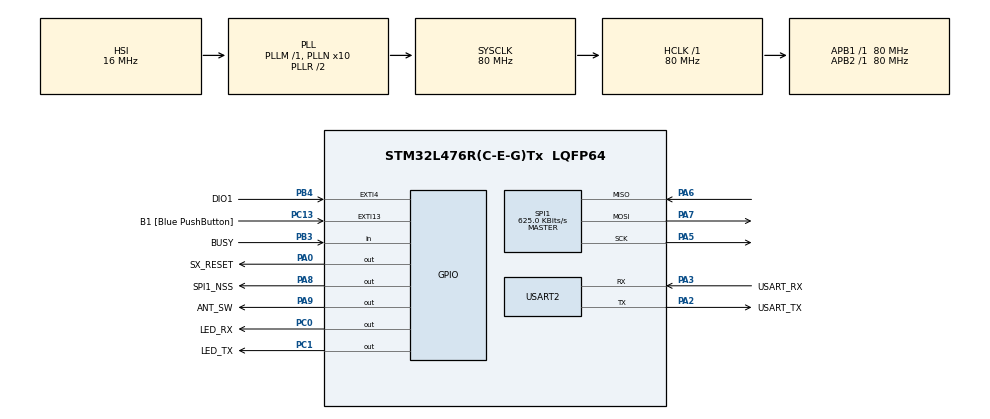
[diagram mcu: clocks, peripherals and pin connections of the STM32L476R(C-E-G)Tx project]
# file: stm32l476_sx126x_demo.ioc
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Mcu.Family=STM32L4
Mcu.Name=STM32L476R(C-E-G)Tx
Mcu.Package=LQFP64
NVIC.EXTI15_10_IRQn=true\:0\:0\:false\:false\:true\:true\:true
NVIC.EXTI4_IRQn=true\:0\:0\:false\:false\:true\:true\:true
NVIC.PriorityGroup=NVIC_PRIORITYGROUP_4
NVIC.RTC_Alarm_IRQn=true\:1\:0\:true\:false\:true\:true\:true
PA0.GPIO_Label=SX_RESET
PA0.Signal=GPIO_Output
PA13\ (JTMS-SWDIO).GPIO_Label=TMS
PA13\ (JTMS-SWDIO).Mode=Serial_Wire
PA13\ (JTMS-SWDIO).Signal=SYS_JTMS-SWDIO
PA14\ (JTCK-SWCLK).GPIO_Label=TCK
PA14\ (JTCK-SWCLK).Mode=Serial_Wire
PA14\ (JTCK-SWCLK).Signal=SYS_JTCK-SWCLK
PA2.GPIO_Label=USART_TX
PA2.GPIO_Mode=GPIO_MODE_AF_PP
PA2.GPIO_PuPd=GPIO_NOPULL
PA2.GPIO_Speed=GPIO_SPEED_FREQ_VERY_HIGH
PA2.Mode=Asynchronous
PA2.Signal=USART2_TX
PA3.GPIO_Label=USART_RX
PA3.GPIO_Mode=GPIO_MODE_AF_PP
PA3.GPIO_PuPd=GPIO_PULLUP
PA3.GPIO_Speed=GPIO_SPEED_FREQ_VERY_HIGH
PA3.Mode=Asynchronous
PA3.Signal=USART2_RX
PA5.Mode=Full_Duplex_Master
PA5.Signal=SPI1_SCK
PA6.Mode=Full_Duplex_Master
PA6.Signal=SPI1_MISO
PA7.Mode=Full_Duplex_Master
PA7.Signal=SPI1_MOSI
PA8.GPIO_Label=SPI1_NSS
PA8.PinState=GPIO_PIN_SET
PA8.Signal=GPIO_Output
PA9.GPIO_Label=ANT_SW
PA9.Signal=GPIO_Output
PB3\ (JTDO-TRACESWO).GPIO_Label=BUSY
PB3\ (JTDO-TRACESWO).GPIO_PuPd=GPIO_PULLUP
PB3\ (JTDO-TRACESWO).Signal=GPIO_Input
PB4\ (NJTRST).GPIO_Label=DIO1
PB4\ (NJTRST).GPIO_PuPd=GPIO_PULLUP
PB4\ (NJTRST).Signal=GPXTI4
PC0.GPIO_Label=LED_RX
PC0.Signal=GPIO_Output
PC1.GPIO_Label=LED_TX
PC1.Signal=GPIO_Output
PC13.GPIO_Label=B1 [Blue PushButton]
PC13.GPIO_ModeDefaultEXTI=GPIO_MODE_IT_FALLING
PC13.GPIO_PuPd=GPIO_NOPULL
PC13.Signal=GPXTI13
PC14-OSC32_IN\ (PC14).Mode=LSE-External-Oscillator
PC14-OSC32_IN\ (PC14).Signal=RCC_OSC32_IN
PC15-OSC32_OUT\ (PC15).Mode=LSE-External-Oscillator
PC15-OSC32_OUT\ (PC15).Signal=RCC_OSC32_OUT
ProjectManager.HeapSize=0x200
ProjectManager.StackSize=0x400
ProjectManager.TargetToolchain=Makefile
RCC.ADCFreq_Value=64000000
RCC.AHBFreq_Value=80000000
RCC.APB1Freq_Value=80000000
RCC.APB1TimFreq_Value=80000000
RCC.APB2Freq_Value=80000000
RCC.APB2TimFreq_Value=80000000
RCC.CortexFreq_Value=80000000
RCC.HCLKFreq_Value=80000000
RCC.HSE_VALUE=8000000
RCC.HSI_VALUE=16000000
RCC.MSI_VALUE=4000000
RCC.PLLN=10
RCC.PLLSourceVirtual=RCC_PLLSOURCE_HSI
RCC.PREFETCH_ENABLE=1
RCC.SYSCLKFreq_VALUE=80000000
RCC.SYSCLKSource=RCC_SYSCLKSOURCE_PLLCLK
RCC.USBFreq_Value=64000000
RCC.VCOOutputFreq_Value=160000000
RTC.Alarm-Alarm\ A=RTC_ALARM_A
RTC.AsynchPrediv=31
RTC.Format=RTC_FORMAT_BIN
RTC.SynchPrediv=1023
SPI1.BaudRatePrescaler=SPI_BAUDRATEPRESCALER_128
SPI1.CLKPhase=SPI_PHASE_2EDGE
SPI1.CalculateBaudRate=625.0 KBits/s
SPI1.DataSize=SPI_DATASIZE_8BIT
SPI1.Direction=SPI_DIRECTION_2LINES
SPI1.Mode=SPI_MODE_MASTER
SPI1.VirtualType=VM_MASTER
USART2.VirtualMode-Asynchronous=VM_ASYNC
VP_RTC_VS_RTC_Activate.Mode=RTC_Enabled
VP_RTC_VS_RTC_Alarm_A_Intern.Mode=Alarm A
VP_RTC_VS_RTC_Calendar.Mode=RTC_Calendar
board=NUCLEO-L476RG

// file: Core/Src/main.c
/* USER CODE BEGIN Header */
/**
  ******************************************************************************
  * @file           : main.c
  * @brief          : Main program body
  ******************************************************************************
  * @attention
  *
  * <h2><center>&copy; Copyright (c) 2021 STMicroelectronics.
  * All rights reserved.</center></h2>
  *
  * This software component is licensed by ST under BSD 3-Clause license,
  * the "License"; You may not use this file except in compliance with the
  * License. You may obtain a copy of the License at:
  *                        opensource.org/licenses/BSD-3-Clause
  *
  ******************************************************************************
  */
/* USER CODE END Header */
#include "main.h"

/* USER CODE BEGIN Includes */
#include "app_sx126x.h"
/* USER CODE END Includes */

RTC_HandleTypeDef hrtc;

SPI_HandleTypeDef hspi1;

UART_HandleTypeDef huart2;

void SystemClock_Config(void);
static void MX_GPIO_Init(void);
static void MX_SPI1_Init(void);
static void MX_USART2_UART_Init(void);
static void MX_RTC_Init(void);

/* USER CODE BEGIN 0 */
int _write(int fd, char *pBuffer, int size)
{
  for (int i = 0; i < size; i++)
  {
    HAL_UART_Transmit(&huart2, (uint8_t *)(pBuffer+i), 1, 1000);
  }
  return size;
}
/* USER CODE END 0 */

int main(void)
{

  /* MCU Configuration--------------------------------------------------------*/

  /* Reset of all peripherals, Initializes the Flash interface and the Systick. */
  HAL_Init();

  /* Configure the system clock */
  SystemClock_Config();

  /* Initialize all configured peripherals */
  MX_GPIO_Init();
  MX_SPI1_Init();
  MX_USART2_UART_Init();
  MX_RTC_Init();
  /* USER CODE BEGIN 2 */
  sx126x_init();
  /* USER CODE END 2 */

  /* Infinite loop */
  /* USER CODE BEGIN WHILE */
  while (1)
  {
    // printf("this is sx126x application\n");
    // sx126x_rx_packet();
    register_test();
    // sx126x_tx_packet(0,0);
    HAL_Delay(100);
    // sx126x_rx_packet();
    // packet_rx();

    // printf("tx packet\n");
    /* USER CODE END WHILE */

  }
}

void SystemClock_Config(void)
{
  RCC_OscInitTypeDef RCC_OscInitStruct = {0};
  RCC_ClkInitTypeDef RCC_ClkInitStruct = {0};
  RCC_PeriphCLKInitTypeDef PeriphClkInit = {0};

  /** Initializes the RCC Oscillators according to the specified parameters
  * in the RCC_OscInitTypeDef structure.
  */
  RCC_OscInitStruct.OscillatorType = RCC_OSCILLATORTYPE_HSI|RCC_OSCILLATORTYPE_LSI;
  RCC_OscInitStruct.HSIState = RCC_HSI_ON;
  RCC_OscInitStruct.HSICalibrationValue = RCC_HSICALIBRATION_DEFAULT;
  RCC_OscInitStruct.LSIState = RCC_LSI_ON;
  RCC_OscInitStruct.PLL.PLLState = RCC_PLL_ON;
  RCC_OscInitStruct.PLL.PLLSource = RCC_PLLSOURCE_HSI;
  RCC_OscInitStruct.PLL.PLLM = 1;
  RCC_OscInitStruct.PLL.PLLN = 10;
  RCC_OscInitStruct.PLL.PLLP = RCC_PLLP_DIV7;
  RCC_OscInitStruct.PLL.PLLQ = RCC_PLLQ_DIV2;
  RCC_OscInitStruct.PLL.PLLR = RCC_PLLR_DIV2;
  if (HAL_RCC_OscConfig(&RCC_OscInitStruct) != HAL_OK)
  {
    Error_Handler();
  }
  /** Initializes the CPU, AHB and APB buses clocks
  */
  RCC_ClkInitStruct.ClockType = RCC_CLOCKTYPE_HCLK|RCC_CLOCKTYPE_SYSCLK
                              |RCC_CLOCKTYPE_PCLK1|RCC_CLOCKTYPE_PCLK2;
  RCC_ClkInitStruct.SYSCLKSource = RCC_SYSCLKSOURCE_PLLCLK;
  RCC_ClkInitStruct.AHBCLKDivider = RCC_SYSCLK_DIV1;
  RCC_ClkInitStruct.APB1CLKDivider = RCC_HCLK_DIV1;
  RCC_ClkInitStruct.APB2CLKDivider = RCC_HCLK_DIV1;

  if (HAL_RCC_ClockConfig(&RCC_ClkInitStruct, FLASH_LATENCY_4) != HAL_OK)
  {
    Error_Handler();
  }
  PeriphClkInit.PeriphClockSelection = RCC_PERIPHCLK_RTC|RCC_PERIPHCLK_USART2;
  PeriphClkInit.Usart2ClockSelection = RCC_USART2CLKSOURCE_PCLK1;
  PeriphClkInit.RTCClockSelection = RCC_RTCCLKSOURCE_LSI;
  if (HAL_RCCEx_PeriphCLKConfig(&PeriphClkInit) != HAL_OK)
  {
    Error_Handler();
  }
  /** Configure the main internal regulator output voltage
  */
  if (HAL_PWREx_ControlVoltageScaling(PWR_REGULATOR_VOLTAGE_SCALE1) != HAL_OK)
  {
    Error_Handler();
  }
}

static void MX_RTC_Init(void)
{

  RTC_TimeTypeDef sTime = {0};
  RTC_DateTypeDef sDate = {0};
  RTC_AlarmTypeDef sAlarm = {0};

  /** Initialize RTC Only
  */
  hrtc.Instance = RTC;
  hrtc.Init.HourFormat = RTC_HOURFORMAT_24;
  hrtc.Init.AsynchPrediv = 31;
  hrtc.Init.SynchPrediv = 1023;
  hrtc.Init.OutPut = RTC_OUTPUT_DISABLE;
  hrtc.Init.OutPutRemap = RTC_OUTPUT_REMAP_NONE;
  hrtc.Init.OutPutPolarity = RTC_OUTPUT_POLARITY_HIGH;
  hrtc.Init.OutPutType = RTC_OUTPUT_TYPE_OPENDRAIN;
  if (HAL_RTC_Init(&hrtc) != HAL_OK)
  {
    Error_Handler();
  }

  /** Initialize RTC and set the Time and Date
  */
  sTime.Hours = 0;
  sTime.Minutes = 0;
  sTime.Seconds = 0;
  sTime.DayLightSaving = RTC_DAYLIGHTSAVING_NONE;
  sTime.StoreOperation = RTC_STOREOPERATION_RESET;
  if (HAL_RTC_SetTime(&hrtc, &sTime, RTC_FORMAT_BIN) != HAL_OK)
  {
    Error_Handler();
  }
  sDate.WeekDay = RTC_WEEKDAY_MONDAY;
  sDate.Month = RTC_MONTH_JANUARY;
  sDate.Date = 1;
  sDate.Year = 0;

  if (HAL_RTC_SetDate(&hrtc, &sDate, RTC_FORMAT_BIN) != HAL_OK)
  {
    Error_Handler();
  }
  /** Enable the Alarm A
  */
  sAlarm.AlarmTime.Hours = 0;
  sAlarm.AlarmTime.Minutes = 0;
  sAlarm.AlarmTime.Seconds = 0;
  sAlarm.AlarmTime.SubSeconds = 0;
  sAlarm.AlarmTime.DayLightSaving = RTC_DAYLIGHTSAVING_NONE;
  sAlarm.AlarmTime.StoreOperation = RTC_STOREOPERATION_RESET;
  sAlarm.AlarmMask = RTC_ALARMMASK_NONE;
  sAlarm.AlarmSubSecondMask = RTC_ALARMSUBSECONDMASK_ALL;
  sAlarm.AlarmDateWeekDaySel = RTC_ALARMDATEWEEKDAYSEL_DATE;
  sAlarm.AlarmDateWeekDay = 1;
  sAlarm.Alarm = RTC_ALARM_A;
  if (HAL_RTC_SetAlarm_IT(&hrtc, &sAlarm, RTC_FORMAT_BIN) != HAL_OK)
  {
    Error_Handler();
  }

}

static void MX_SPI1_Init(void)
{

  /* SPI1 parameter configuration*/
  hspi1.Instance = SPI1;
  hspi1.Init.Mode = SPI_MODE_MASTER;
  hspi1.Init.Direction = SPI_DIRECTION_2LINES;
  hspi1.Init.DataSize = SPI_DATASIZE_8BIT;
  hspi1.Init.CLKPolarity = SPI_POLARITY_LOW;
  hspi1.Init.CLKPhase = SPI_PHASE_2EDGE;
  hspi1.Init.NSS = SPI_NSS_SOFT;
  hspi1.Init.BaudRatePrescaler = SPI_BAUDRATEPRESCALER_128;
  hspi1.Init.FirstBit = SPI_FIRSTBIT_MSB;
  hspi1.Init.TIMode = SPI_TIMODE_DISABLE;
  hspi1.Init.CRCCalculation = SPI_CRCCALCULATION_DISABLE;
  hspi1.Init.CRCPolynomial = 7;
  hspi1.Init.CRCLength = SPI_CRC_LENGTH_DATASIZE;
  hspi1.Init.NSSPMode = SPI_NSS_PULSE_DISABLE;
  if (HAL_SPI_Init(&hspi1) != HAL_OK)
  {
    Error_Handler();
  }

}

static void MX_USART2_UART_Init(void)
{

  huart2.Instance = USART2;
  huart2.Init.BaudRate = 115200;
  huart2.Init.WordLength = UART_WORDLENGTH_8B;
  huart2.Init.StopBits = UART_STOPBITS_1;
  huart2.Init.Parity = UART_PARITY_NONE;
  huart2.Init.Mode = UART_MODE_TX_RX;
  huart2.Init.HwFlowCtl = UART_HWCONTROL_NONE;
  huart2.Init.OverSampling = UART_OVERSAMPLING_16;
  huart2.Init.OneBitSampling = UART_ONE_BIT_SAMPLE_DISABLE;
  huart2.AdvancedInit.AdvFeatureInit = UART_ADVFEATURE_NO_INIT;
  if (HAL_UART_Init(&huart2) != HAL_OK)
  {
    Error_Handler();
  }

}

static void MX_GPIO_Init(void)
{
  GPIO_InitTypeDef GPIO_InitStruct = {0};

  /* GPIO Ports Clock Enable */
  __HAL_RCC_GPIOC_CLK_ENABLE();
  __HAL_RCC_GPIOA_CLK_ENABLE();
  __HAL_RCC_GPIOB_CLK_ENABLE();

  /*Configure GPIO pin Output Level */
  HAL_GPIO_WritePin(GPIOC, LED_RX_Pin|LED_TX_Pin, GPIO_PIN_RESET);

  /*Configure GPIO pin Output Level */
  HAL_GPIO_WritePin(GPIOA, SX_RESET_Pin|ANT_SW_Pin, GPIO_PIN_RESET);

  /*Configure GPIO pin Output Level */
  HAL_GPIO_WritePin(SPI1_NSS_GPIO_Port, SPI1_NSS_Pin, GPIO_PIN_SET);

  /*Configure GPIO pin : B1_Pin */
  GPIO_InitStruct.Pin = B1_Pin;
  GPIO_InitStruct.Mode = GPIO_MODE_IT_FALLING;
  GPIO_InitStruct.Pull = GPIO_NOPULL;
  HAL_GPIO_Init(B1_GPIO_Port, &GPIO_InitStruct);

  /*Configure GPIO pins : LED_RX_Pin LED_TX_Pin */
  GPIO_InitStruct.Pin = LED_RX_Pin|LED_TX_Pin;
  GPIO_InitStruct.Mode = GPIO_MODE_OUTPUT_PP;
  GPIO_InitStruct.Pull = GPIO_NOPULL;
  GPIO_InitStruct.Speed = GPIO_SPEED_FREQ_LOW;
  HAL_GPIO_Init(GPIOC, &GPIO_InitStruct);

  /*Configure GPIO pins : SX_RESET_Pin SPI1_NSS_Pin ANT_SW_Pin */
  GPIO_InitStruct.Pin = SX_RESET_Pin|SPI1_NSS_Pin|ANT_SW_Pin;
  GPIO_InitStruct.Mode = GPIO_MODE_OUTPUT_PP;
  GPIO_InitStruct.Pull = GPIO_NOPULL;
  GPIO_InitStruct.Speed = GPIO_SPEED_FREQ_LOW;
  HAL_GPIO_Init(GPIOA, &GPIO_InitStruct);

  /*Configure GPIO pin : BUSY_Pin */
  GPIO_InitStruct.Pin = BUSY_Pin;
  GPIO_InitStruct.Mode = GPIO_MODE_INPUT;
  GPIO_InitStruct.Pull = GPIO_PULLUP;
  HAL_GPIO_Init(BUSY_GPIO_Port, &GPIO_InitStruct);

  /*Configure GPIO pin : DIO1_Pin */
  GPIO_InitStruct.Pin = DIO1_Pin;
  GPIO_InitStruct.Mode = GPIO_MODE_IT_RISING;
  GPIO_InitStruct.Pull = GPIO_PULLUP;
  HAL_GPIO_Init(DIO1_GPIO_Port, &GPIO_InitStruct);

  /* EXTI interrupt init*/
  HAL_NVIC_SetPriority(EXTI4_IRQn, 0, 0);
  HAL_NVIC_EnableIRQ(EXTI4_IRQn);

  HAL_NVIC_SetPriority(EXTI15_10_IRQn, 0, 0);
  HAL_NVIC_EnableIRQ(EXTI15_10_IRQn);

}

void Error_Handler(void)
{
  __disable_irq();
  while (1)
  {
  }
}

// #ifdef  USE_FULL_ASSERT
// /**
//   * @brief  Reports the name of the source file and the source line number
//   *         where the assert_param error has occurred.
//   * @param  file: pointer to the source file name
//   * @param  line: assert_param error line source number
//   * @retval None
//   */
// void assert_failed(uint8_t *file, uint32_t line)
// {
//   /* USER CODE BEGIN 6 */
// //   /* User can add his own implementation to report the file name and line number,
// //      ex: printf("Wrong parameters value: file %s on line %d\r\n", file, line) */
//   /* USER CODE END 6 */
// }
// #endif /* USE_FULL_ASSERT */

/************************ (C) COPYRIGHT STMicroelectronics *****END OF FILE****/
